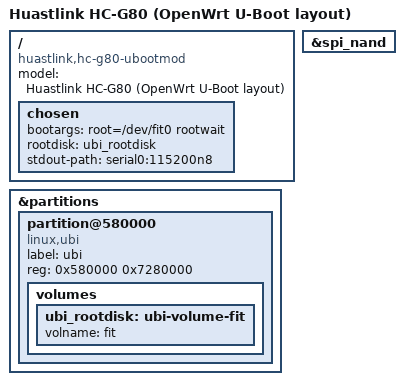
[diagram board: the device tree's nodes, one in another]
// SPDX-License-Identifier: GPL-2.0-or-later OR MIT
/dts-v1/;
#include "mt7981b-huastlink-hc-g80.dtsi"

/ {
	model = "Huastlink HC-G80 (OpenWrt U-Boot layout)";
	compatible = "huastlink,hc-g80-ubootmod", "mediatek,mt7981b";

	chosen {
		bootargs = "root=/dev/fit0 rootwait";
		rootdisk = <&ubi_rootdisk>;
		stdout-path = "serial0:115200n8";
	};
};

&spi_nand {
	/delete-property/ mediatek,nmbm;
	/delete-property/ mediatek,bmt-max-ratio;
	/delete-property/ mediatek,bmt-max-reserved-blocks;
};

&partitions {
	/* keep u-bootmod fixed layout explicitly */
	partition@580000 {
		compatible = "linux,ubi";
		label = "ubi";
		reg = <0x580000 0x7280000>;
		volumes {
			ubi_rootdisk: ubi-volume-fit { volname = "fit"; };
		};
	};
};
